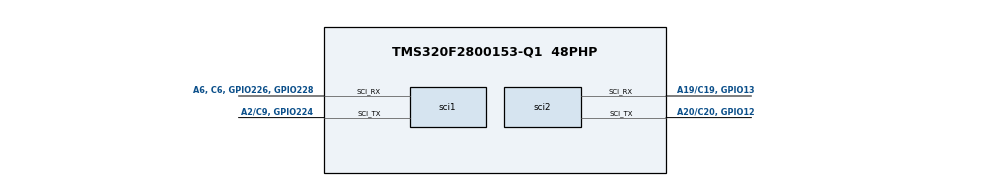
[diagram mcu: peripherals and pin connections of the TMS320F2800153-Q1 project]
/**
 * These arguments were used when this file was generated. They will be automatically applied on subsequent loads
 * via the GUI or CLI. Run CLI with '--help' for additional information on how to override these arguments.
 * @cliArgs --device "F280015x" --part "F280015x_48PHP" --package "48PHP" --context "system" --product "C2000WARE@5.04.00.00"
 * @v2CliArgs --device "TMS320F2800153-Q1" --package "48PHP" --context "system" --product "C2000WARE@5.04.00.00"
 * @versions {"tool":"1.21.0+3721"}
 */

/**
 * Import the modules used in this configuration.
 */
const sci    = scripting.addModule("/driverlib/sci.js", {}, false);
const sci1   = sci.addInstance();
const sci2   = sci.addInstance();
const sysctl = scripting.addModule("/driverlib/sysctl.js");

/**
 * Write custom configuration values to the imported modules.
 */
sci1.$name                 = "Master_uart";
sci1.sci.$assign           = "SCIC";
sci1.sci.sci_rxPin.$assign = "A6, C6, GPIO226, GPIO228";
sci1.sci.sci_txPin.$assign = "A2/C9, GPIO224";
sci1.rxQual.$name          = "myGPIOQUAL0";
sci1.txQual.$name          = "myGPIOQUAL1";

sci2.$name                 = "ACU_uart";
sci2.sci.$assign           = "SCIB";
sci2.sci.sci_rxPin.$assign = "A19/C19, GPIO13";
sci2.sci.sci_txPin.$assign = "A20/C20, GPIO12";
sci2.rxQual.$name          = "myGPIOQUAL2";
sci2.txQual.$name          = "myGPIOQUAL3";
